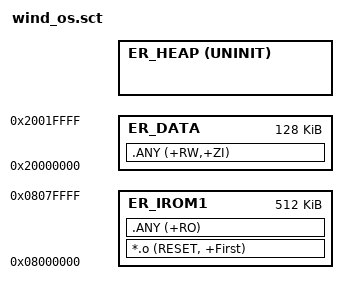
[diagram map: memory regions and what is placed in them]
; *************************************************************
; *** Scatter-Loading Description File generated by uVision ***
; *************************************************************

LR_IROM1 0x08000000 0x00080000  {    ; load region size_region
  ER_IROM1 0x08000000 0x00080000  {  ; load address = execution address
   *.o (RESET, +First)
   ;*(InRoot$$Sections)
   .ANY (+RO)
  }
  ER_DATA 0x20000000  0x20000 {  ; RW data
   .ANY (+RW,+ZI)
  }
  ER_HEAP +0 UNINIT {  ; RW data
	
  }
}
